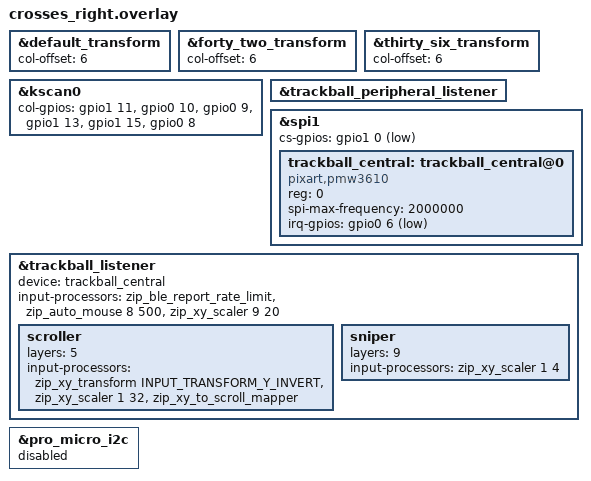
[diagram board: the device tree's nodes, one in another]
/*
 * Copyright (c) 2025 Vincent Franco
 * SPDX-License-Identifier: MIT
 */

#include "crosses.dtsi"
#include "input_processors.dtsi"
#include <zephyr/dt-bindings/input/input-event-codes.h>
#include <dt-bindings/zmk/input_transform.h>

&default_transform {
  col-offset = <6>;
};

&forty_two_transform {
  col-offset = <6>;
};

&thirty_six_transform {
  col-offset = <6>;
};

&kscan0 {
  col-gpios
    = <&gpio1 11 (GPIO_ACTIVE_HIGH | GPIO_PULL_DOWN)>
    , <&gpio0 10  (GPIO_ACTIVE_HIGH | GPIO_PULL_DOWN)>
    , <&gpio0 9 (GPIO_ACTIVE_HIGH | GPIO_PULL_DOWN)>
    , <&gpio1 13 (GPIO_ACTIVE_HIGH | GPIO_PULL_DOWN)>
    , <&gpio1 15 (GPIO_ACTIVE_HIGH | GPIO_PULL_DOWN)>
    , <&gpio0 8 (GPIO_ACTIVE_HIGH | GPIO_PULL_DOWN)>
    ;

};

&trackball_peripheral_listener {
  status = "okay";
};

&spi1 {
  cs-gpios = <&gpio1 0 GPIO_ACTIVE_LOW>;

  trackball_central: trackball_central@0 {
    status = "okay";
    compatible = "pixart,pmw3610";
    reg = <0>;
    spi-max-frequency = <2000000>;
    irq-gpios = <&gpio0 6 (GPIO_ACTIVE_LOW | GPIO_PULL_UP)>;
  };
};

// Overrides for the input listener node
&trackball_listener {
  status = "okay";
  device = <&trackball_central>;
  input-processors = <&zip_ble_report_rate_limit>,
                     <&zip_auto_mouse 8 500>,
                     <&zip_xy_scaler 9 20>;

  scroller {
    layers = <5>;
    input-processors =
      <&zip_xy_transform INPUT_TRANSFORM_Y_INVERT>,
      <&zip_xy_scaler 1 32>,
      <&zip_xy_to_scroll_mapper>;
  };

  sniper {
    layers = <9>;
    input-processors = <&zip_xy_scaler 1 4>;
  };
};

&pro_micro_i2c {
    status = "disabled";
};
